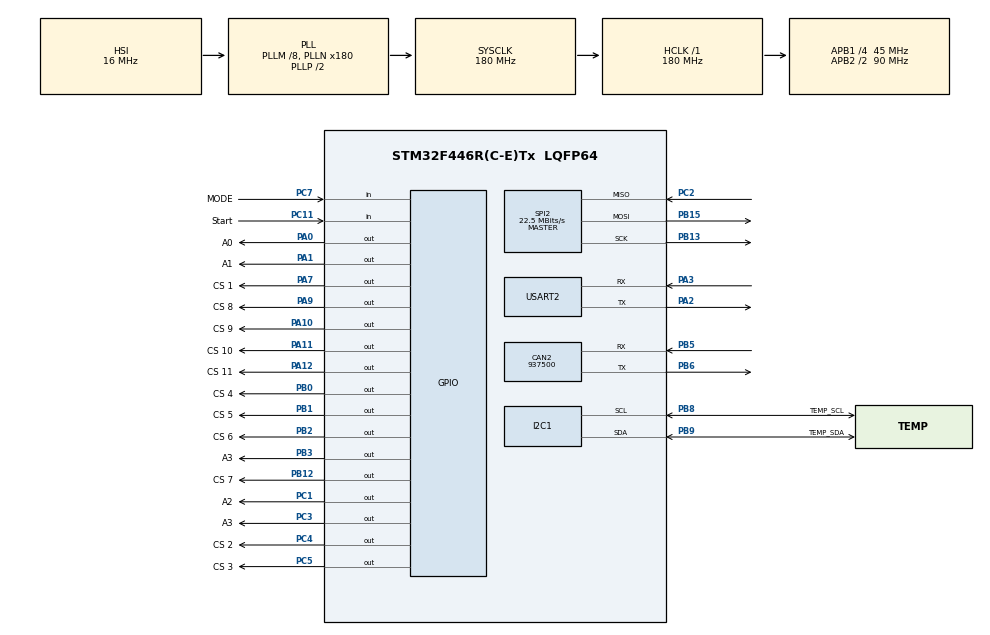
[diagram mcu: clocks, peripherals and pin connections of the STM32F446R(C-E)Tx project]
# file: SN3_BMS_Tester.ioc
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CAN2.CalculateBaudRate=937500
CAN2.CalculateTimeBit=1066
CAN2.CalculateTimeQuantum=355.55555555555554
Mcu.Family=STM32F4
Mcu.Name=STM32F446R(C-E)Tx
Mcu.Package=LQFP64
NVIC.PriorityGroup=NVIC_PRIORITYGROUP_4
PA0-WKUP.GPIO_Label=A0
PA0-WKUP.Signal=GPIO_Output
PA1.GPIO_Label=A1
PA1.Signal=GPIO_Output
PA10.GPIO_Label=CS 9
PA10.Signal=GPIO_Output
PA11.GPIO_Label=CS 10
PA11.Signal=GPIO_Output
PA12.GPIO_Label=CS 11
PA12.Signal=GPIO_Output
PA2.Mode=Asynchronous
PA2.Signal=USART2_TX
PA3.Mode=Asynchronous
PA3.Signal=USART2_RX
PA7.GPIO_Label=CS 1
PA7.Signal=GPIO_Output
PA9.GPIO_Label=CS 8
PA9.Signal=GPIO_Output
PB0.GPIO_Label=CS 4
PB0.Signal=GPIO_Output
PB1.GPIO_Label=CS 5
PB1.Signal=GPIO_Output
PB12.GPIO_Label=CS 7
PB12.Signal=GPIO_Output
PB13.Mode=Full_Duplex_Master
PB13.Signal=SPI2_SCK
PB15.Mode=Full_Duplex_Master
PB15.Signal=SPI2_MOSI
PB2.GPIO_Label=CS 6
PB2.Signal=GPIO_Output
PB3.GPIO_Label=A3
PB3.Signal=GPIO_Output
PB5.Mode=CAN_Activate
PB5.Signal=CAN2_RX
PB6.Mode=CAN_Activate
PB6.Signal=CAN2_TX
PB8.GPIO_Label=TEMP_SCL
PB8.Mode=I2C
PB8.Signal=I2C1_SCL
PB9.GPIO_Label=TEMP_SDA
PB9.Mode=I2C
PB9.Signal=I2C1_SDA
PC1.GPIO_Label=A2
PC1.Signal=GPIO_Output
PC11.GPIO_Label=Start
PC11.Signal=GPIO_Input
PC2.Mode=Full_Duplex_Master
PC2.Signal=SPI2_MISO
PC3.GPIO_Label=A3
PC3.Signal=GPIO_Output
PC4.GPIO_Label=CS 2
PC4.Signal=GPIO_Output
PC5.GPIO_Label=CS 3
PC5.Signal=GPIO_Output
PC7.GPIO_Label=MODE
PC7.Signal=GPIO_Input
ProjectManager.HeapSize=0x200
ProjectManager.StackSize=0x400
ProjectManager.TargetToolchain=STM32CubeIDE
RCC.AHBFreq_Value=180000000
RCC.APB1CLKDivider=RCC_HCLK_DIV4
RCC.APB1Freq_Value=45000000
RCC.APB1TimFreq_Value=90000000
RCC.APB2CLKDivider=RCC_HCLK_DIV2
RCC.APB2Freq_Value=90000000
RCC.APB2TimFreq_Value=180000000
RCC.CortexFreq_Value=180000000
RCC.HCLKFreq_Value=180000000
RCC.PLLM=8
RCC.PLLN=180
RCC.SYSCLKFreq_VALUE=180000000
RCC.SYSCLKSource=RCC_SYSCLKSOURCE_PLLCLK
RCC.USBFreq_Value=180000000
RCC.VCOOutputFreq_Value=360000000
SPI2.CalculateBaudRate=22.5 MBits/s
SPI2.Direction=SPI_DIRECTION_2LINES
SPI2.Mode=SPI_MODE_MASTER
SPI2.VirtualType=VM_MASTER
USART2.VirtualMode=VM_ASYNC
board=custom

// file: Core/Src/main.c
/* USER CODE BEGIN Header */
/**
  ******************************************************************************
  * @file           : main.c
  * @brief          : Main program body
  ******************************************************************************
  * @attention
  *
  * Copyright (c) 2023 STMicroelectronics.
  * All rights reserved.
  *
  * This software is licensed under terms that can be found in the LICENSE file
  * in the root directory of this software component.
  * If no LICENSE file comes with this software, it is provided AS-IS.
  *
  ******************************************************************************
  */
/* USER CODE END Header */
#include "main.h"

CAN_HandleTypeDef hcan2;

I2C_HandleTypeDef hi2c1;

SPI_HandleTypeDef hspi2;

UART_HandleTypeDef huart2;

void SystemClock_Config(void);
static void MX_GPIO_Init(void);
static void MX_I2C1_Init(void);
static void MX_SPI2_Init(void);
static void MX_USART2_UART_Init(void);
static void MX_CAN2_Init(void);

int main(void)
{

  /* MCU Configuration--------------------------------------------------------*/

  /* Reset of all peripherals, Initializes the Flash interface and the Systick. */
  HAL_Init();

  /* Configure the system clock */
  SystemClock_Config();

  /* Initialize all configured peripherals */
  MX_GPIO_Init();
  MX_I2C1_Init();
  MX_SPI2_Init();
  MX_USART2_UART_Init();
  MX_CAN2_Init();

  /* Infinite loop */
  while (1)
  {

    /* USER CODE BEGIN 3 */

	  FEB_Main_Loop();
  }
  /* USER CODE END 3 */
}

void SystemClock_Config(void)
{
  RCC_OscInitTypeDef RCC_OscInitStruct = {0};
  RCC_ClkInitTypeDef RCC_ClkInitStruct = {0};

  /** Configure the main internal regulator output voltage
  */
  __HAL_RCC_PWR_CLK_ENABLE();
  __HAL_PWR_VOLTAGESCALING_CONFIG(PWR_REGULATOR_VOLTAGE_SCALE1);

  /** Initializes the RCC Oscillators according to the specified parameters
  * in the RCC_OscInitTypeDef structure.
  */
  RCC_OscInitStruct.OscillatorType = RCC_OSCILLATORTYPE_HSI;
  RCC_OscInitStruct.HSIState = RCC_HSI_ON;
  RCC_OscInitStruct.HSICalibrationValue = RCC_HSICALIBRATION_DEFAULT;
  RCC_OscInitStruct.PLL.PLLState = RCC_PLL_ON;
  RCC_OscInitStruct.PLL.PLLSource = RCC_PLLSOURCE_HSI;
  RCC_OscInitStruct.PLL.PLLM = 8;
  RCC_OscInitStruct.PLL.PLLN = 180;
  RCC_OscInitStruct.PLL.PLLP = RCC_PLLP_DIV2;
  RCC_OscInitStruct.PLL.PLLQ = 2;
  RCC_OscInitStruct.PLL.PLLR = 2;
  if (HAL_RCC_OscConfig(&RCC_OscInitStruct) != HAL_OK)
  {
    Error_Handler();
  }

  /** Activate the Over-Drive mode
  */
  if (HAL_PWREx_EnableOverDrive() != HAL_OK)
  {
    Error_Handler();
  }

  /** Initializes the CPU, AHB and APB buses clocks
  */
  RCC_ClkInitStruct.ClockType = RCC_CLOCKTYPE_HCLK|RCC_CLOCKTYPE_SYSCLK
                              |RCC_CLOCKTYPE_PCLK1|RCC_CLOCKTYPE_PCLK2;
  RCC_ClkInitStruct.SYSCLKSource = RCC_SYSCLKSOURCE_PLLCLK;
  RCC_ClkInitStruct.AHBCLKDivider = RCC_SYSCLK_DIV1;
  RCC_ClkInitStruct.APB1CLKDivider = RCC_HCLK_DIV4;
  RCC_ClkInitStruct.APB2CLKDivider = RCC_HCLK_DIV2;

  if (HAL_RCC_ClockConfig(&RCC_ClkInitStruct, FLASH_LATENCY_5) != HAL_OK)
  {
    Error_Handler();
  }
}

static void MX_CAN2_Init(void)
{

  hcan2.Instance = CAN2;
  hcan2.Init.Prescaler = 16;
  hcan2.Init.Mode = CAN_MODE_NORMAL;
  hcan2.Init.SyncJumpWidth = CAN_SJW_1TQ;
  hcan2.Init.TimeSeg1 = CAN_BS1_1TQ;
  hcan2.Init.TimeSeg2 = CAN_BS2_1TQ;
  hcan2.Init.TimeTriggeredMode = DISABLE;
  hcan2.Init.AutoBusOff = DISABLE;
  hcan2.Init.AutoWakeUp = DISABLE;
  hcan2.Init.AutoRetransmission = DISABLE;
  hcan2.Init.ReceiveFifoLocked = DISABLE;
  hcan2.Init.TransmitFifoPriority = DISABLE;
  if (HAL_CAN_Init(&hcan2) != HAL_OK)
  {
    Error_Handler();
  }

}

static void MX_I2C1_Init(void)
{

  hi2c1.Instance = I2C1;
  hi2c1.Init.ClockSpeed = 100000;
  hi2c1.Init.DutyCycle = I2C_DUTYCYCLE_2;
  hi2c1.Init.OwnAddress1 = 0;
  hi2c1.Init.AddressingMode = I2C_ADDRESSINGMODE_7BIT;
  hi2c1.Init.DualAddressMode = I2C_DUALADDRESS_DISABLE;
  hi2c1.Init.OwnAddress2 = 0;
  hi2c1.Init.GeneralCallMode = I2C_GENERALCALL_DISABLE;
  hi2c1.Init.NoStretchMode = I2C_NOSTRETCH_DISABLE;
  if (HAL_I2C_Init(&hi2c1) != HAL_OK)
  {
    Error_Handler();
  }

}

static void MX_SPI2_Init(void)
{

  /* SPI2 parameter configuration*/
  hspi2.Instance = SPI2;
  hspi2.Init.Mode = SPI_MODE_MASTER;
  hspi2.Init.Direction = SPI_DIRECTION_2LINES;
  hspi2.Init.DataSize = SPI_DATASIZE_8BIT;
  hspi2.Init.CLKPolarity = SPI_POLARITY_LOW;
  hspi2.Init.CLKPhase = SPI_PHASE_1EDGE;
  hspi2.Init.NSS = SPI_NSS_SOFT;
  hspi2.Init.BaudRatePrescaler = SPI_BAUDRATEPRESCALER_2;
  hspi2.Init.FirstBit = SPI_FIRSTBIT_MSB;
  hspi2.Init.TIMode = SPI_TIMODE_DISABLE;
  hspi2.Init.CRCCalculation = SPI_CRCCALCULATION_DISABLE;
  hspi2.Init.CRCPolynomial = 10;
  if (HAL_SPI_Init(&hspi2) != HAL_OK)
  {
    Error_Handler();
  }

}

static void MX_USART2_UART_Init(void)
{

  huart2.Instance = USART2;
  huart2.Init.BaudRate = 115200;
  huart2.Init.WordLength = UART_WORDLENGTH_8B;
  huart2.Init.StopBits = UART_STOPBITS_1;
  huart2.Init.Parity = UART_PARITY_NONE;
  huart2.Init.Mode = UART_MODE_TX_RX;
  huart2.Init.HwFlowCtl = UART_HWCONTROL_NONE;
  huart2.Init.OverSampling = UART_OVERSAMPLING_16;
  if (HAL_UART_Init(&huart2) != HAL_OK)
  {
    Error_Handler();
  }

}

static void MX_GPIO_Init(void)
{
  GPIO_InitTypeDef GPIO_InitStruct = {0};

  /* GPIO Ports Clock Enable */
  __HAL_RCC_GPIOC_CLK_ENABLE();
  __HAL_RCC_GPIOA_CLK_ENABLE();
  __HAL_RCC_GPIOB_CLK_ENABLE();

  /*Configure GPIO pin Output Level */
  HAL_GPIO_WritePin(GPIOC, A2_Pin|A3_Pin|CS_2_Pin|CS_3_Pin, GPIO_PIN_RESET);

  /*Configure GPIO pin Output Level */
  HAL_GPIO_WritePin(GPIOA, A0_Pin|A1_Pin|CS_1_Pin|CS_8_Pin
                          |CS_9_Pin|CS_10_Pin|CS_11_Pin, GPIO_PIN_RESET);

  /*Configure GPIO pin Output Level */
  HAL_GPIO_WritePin(GPIOB, CS_4_Pin|CS_5_Pin|CS_6_Pin|CS_7_Pin
                          |A3B3_Pin, GPIO_PIN_RESET);

  /*Configure GPIO pins : A2_Pin A3_Pin CS_2_Pin CS_3_Pin */
  GPIO_InitStruct.Pin = A2_Pin|A3_Pin|CS_2_Pin|CS_3_Pin;
  GPIO_InitStruct.Mode = GPIO_MODE_OUTPUT_PP;
  GPIO_InitStruct.Pull = GPIO_NOPULL;
  GPIO_InitStruct.Speed = GPIO_SPEED_FREQ_LOW;
  HAL_GPIO_Init(GPIOC, &GPIO_InitStruct);

  /*Configure GPIO pins : A0_Pin A1_Pin CS_1_Pin CS_8_Pin
                           CS_9_Pin CS_10_Pin CS_11_Pin */
  GPIO_InitStruct.Pin = A0_Pin|A1_Pin|CS_1_Pin|CS_8_Pin
                          |CS_9_Pin|CS_10_Pin|CS_11_Pin;
  GPIO_InitStruct.Mode = GPIO_MODE_OUTPUT_PP;
  GPIO_InitStruct.Pull = GPIO_NOPULL;
  GPIO_InitStruct.Speed = GPIO_SPEED_FREQ_LOW;
  HAL_GPIO_Init(GPIOA, &GPIO_InitStruct);

  /*Configure GPIO pins : CS_4_Pin CS_5_Pin CS_6_Pin CS_7_Pin
                           A3B3_Pin */
  GPIO_InitStruct.Pin = CS_4_Pin|CS_5_Pin|CS_6_Pin|CS_7_Pin
                          |A3B3_Pin;
  GPIO_InitStruct.Mode = GPIO_MODE_OUTPUT_PP;
  GPIO_InitStruct.Pull = GPIO_NOPULL;
  GPIO_InitStruct.Speed = GPIO_SPEED_FREQ_LOW;
  HAL_GPIO_Init(GPIOB, &GPIO_InitStruct);

  /*Configure GPIO pins : MODE_Pin Start_Pin */
  GPIO_InitStruct.Pin = MODE_Pin|Start_Pin;
  GPIO_InitStruct.Mode = GPIO_MODE_INPUT;
  GPIO_InitStruct.Pull = GPIO_NOPULL;
  HAL_GPIO_Init(GPIOC, &GPIO_InitStruct);

}

void Error_Handler(void)
{
  __disable_irq();
  while (1)
  {
  }
}
